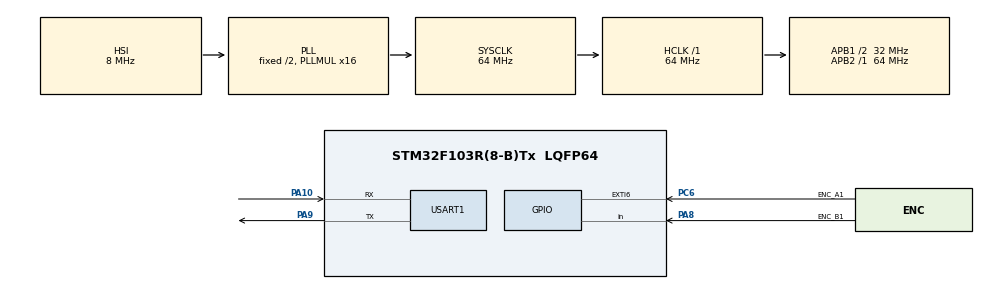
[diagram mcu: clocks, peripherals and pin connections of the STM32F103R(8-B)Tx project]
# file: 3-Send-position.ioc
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Dma.Request0=USART1_TX
Dma.USART1_TX.0.Direction=DMA_MEMORY_TO_PERIPH
Dma.USART1_TX.0.Instance=DMA1_Channel4
Dma.USART1_TX.0.MemDataAlignment=DMA_MDATAALIGN_BYTE
Dma.USART1_TX.0.MemInc=DMA_MINC_ENABLE
Dma.USART1_TX.0.Mode=DMA_NORMAL
Dma.USART1_TX.0.PeriphDataAlignment=DMA_PDATAALIGN_BYTE
Dma.USART1_TX.0.PeriphInc=DMA_PINC_DISABLE
Dma.USART1_TX.0.Priority=DMA_PRIORITY_HIGH
Mcu.Family=STM32F1
Mcu.Name=STM32F103R(8-B)Tx
Mcu.Package=LQFP64
NVIC.DMA1_Channel4_IRQn=true\:0\:0\:false\:false\:true\:false\:true\:true
NVIC.EXTI9_5_IRQn=true\:0\:0\:false\:false\:true\:true\:true\:true
NVIC.PriorityGroup=NVIC_PRIORITYGROUP_4
NVIC.USART1_IRQn=true\:0\:0\:false\:false\:true\:true\:true\:true
PA10.Mode=Asynchronous
PA10.Signal=USART1_RX
PA13.Mode=Serial_Wire
PA13.Signal=SYS_JTMS-SWDIO
PA14.Mode=Serial_Wire
PA14.Signal=SYS_JTCK-SWCLK
PA8.GPIO_Label=ENC_B1
PA8.Signal=GPIO_Input
PA9.Mode=Asynchronous
PA9.Signal=USART1_TX
PC6.GPIO_Label=ENC_A1
PC6.Signal=GPXTI6
ProjectManager.HeapSize=0x200
ProjectManager.StackSize=0x400
ProjectManager.TargetToolchain=MDK-ARM V5.32
RCC.AHBFreq_Value=64000000
RCC.APB1CLKDivider=RCC_HCLK_DIV2
RCC.APB1Freq_Value=32000000
RCC.APB1TimFreq_Value=64000000
RCC.APB2Freq_Value=64000000
RCC.APB2TimFreq_Value=64000000
RCC.HCLKFreq_Value=64000000
RCC.PLLMUL=RCC_PLL_MUL16
RCC.SYSCLKFreq_VALUE=64000000
RCC.SYSCLKSource=RCC_SYSCLKSOURCE_PLLCLK
RCC.USBFreq_Value=64000000
USART1.VirtualMode=VM_ASYNC
board=custom

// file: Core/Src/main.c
/* USER CODE BEGIN Header */
/**
  ******************************************************************************
  * @file           : main.c
  * @brief          : Main program body
  ******************************************************************************
  * @attention
  *
  * Copyright (c) 2026 STMicroelectronics.
  * All rights reserved.
  *
  * This software is licensed under terms that can be found in the LICENSE file
  * in the root directory of this software component.
  * If no LICENSE file comes with this software, it is provided AS-IS.
  *
  ******************************************************************************
  */
/* USER CODE END Header */
#include "main.h"

/* USER CODE BEGIN Includes */
#include "MyApp.h"
#include "ReadENC.h"
#include "command_parser.h"

/* USER CODE END Includes */

UART_HandleTypeDef huart1;
DMA_HandleTypeDef hdma_usart1_tx;

void SystemClock_Config(void);
static void MX_GPIO_Init(void);
static void MX_DMA_Init(void);
static void MX_USART1_UART_Init(void);

int main(void)
{

  /* MCU Configuration--------------------------------------------------------*/

  /* Reset of all peripherals, Initializes the Flash interface and the Systick. */
  HAL_Init();

  /* USER CODE BEGIN Init */
	Encoder_Init();

  /* USER CODE END Init */

  /* Configure the system clock */
  SystemClock_Config();

  /* Initialize all configured peripherals */
  MX_GPIO_Init();
  MX_DMA_Init();
  MX_USART1_UART_Init();
  /* USER CODE BEGIN 2 */
	UART_RX_IT_Init();
  /* USER CODE END 2 */

  /* Infinite loop */
  while (1)
  {

    /* USER CODE BEGIN 3 */

		UART_TX_Task();
		My_App();
  }
  /* USER CODE END 3 */
}

void SystemClock_Config(void)
{
  RCC_OscInitTypeDef RCC_OscInitStruct = {0};
  RCC_ClkInitTypeDef RCC_ClkInitStruct = {0};

  /** Initializes the RCC Oscillators according to the specified parameters
  * in the RCC_OscInitTypeDef structure.
  */
  RCC_OscInitStruct.OscillatorType = RCC_OSCILLATORTYPE_HSI;
  RCC_OscInitStruct.HSIState = RCC_HSI_ON;
  RCC_OscInitStruct.HSICalibrationValue = RCC_HSICALIBRATION_DEFAULT;
  RCC_OscInitStruct.PLL.PLLState = RCC_PLL_ON;
  RCC_OscInitStruct.PLL.PLLSource = RCC_PLLSOURCE_HSI_DIV2;
  RCC_OscInitStruct.PLL.PLLMUL = RCC_PLL_MUL16;
  if (HAL_RCC_OscConfig(&RCC_OscInitStruct) != HAL_OK)
  {
    Error_Handler();
  }

  /** Initializes the CPU, AHB and APB buses clocks
  */
  RCC_ClkInitStruct.ClockType = RCC_CLOCKTYPE_HCLK|RCC_CLOCKTYPE_SYSCLK
                              |RCC_CLOCKTYPE_PCLK1|RCC_CLOCKTYPE_PCLK2;
  RCC_ClkInitStruct.SYSCLKSource = RCC_SYSCLKSOURCE_PLLCLK;
  RCC_ClkInitStruct.AHBCLKDivider = RCC_SYSCLK_DIV1;
  RCC_ClkInitStruct.APB1CLKDivider = RCC_HCLK_DIV2;
  RCC_ClkInitStruct.APB2CLKDivider = RCC_HCLK_DIV1;

  if (HAL_RCC_ClockConfig(&RCC_ClkInitStruct, FLASH_LATENCY_2) != HAL_OK)
  {
    Error_Handler();
  }
}

static void MX_USART1_UART_Init(void)
{

  huart1.Instance = USART1;
  huart1.Init.BaudRate = 115200;
  huart1.Init.WordLength = UART_WORDLENGTH_8B;
  huart1.Init.StopBits = UART_STOPBITS_1;
  huart1.Init.Parity = UART_PARITY_NONE;
  huart1.Init.Mode = UART_MODE_TX_RX;
  huart1.Init.HwFlowCtl = UART_HWCONTROL_NONE;
  huart1.Init.OverSampling = UART_OVERSAMPLING_16;
  if (HAL_UART_Init(&huart1) != HAL_OK)
  {
    Error_Handler();
  }
  /* USER CODE BEGIN USART1_Init 2 */
 __HAL_LINKDMA(&huart1, hdmatx, hdma_usart1_tx);
  /* USER CODE END USART1_Init 2 */

}

static void MX_DMA_Init(void)
{

  /* DMA controller clock enable */
  __HAL_RCC_DMA1_CLK_ENABLE();

  /* DMA interrupt init */
  /* DMA1_Channel4_IRQn interrupt configuration */
  HAL_NVIC_SetPriority(DMA1_Channel4_IRQn, 0, 0);
  HAL_NVIC_EnableIRQ(DMA1_Channel4_IRQn);

}

static void MX_GPIO_Init(void)
{
  GPIO_InitTypeDef GPIO_InitStruct = {0};

  /* GPIO Ports Clock Enable */
  __HAL_RCC_GPIOC_CLK_ENABLE();
  __HAL_RCC_GPIOD_CLK_ENABLE();
  __HAL_RCC_GPIOA_CLK_ENABLE();
  __HAL_RCC_GPIOB_CLK_ENABLE();

  /*Configure GPIO pins : PC13 PC14 PC15 PC0
                           PC1 PC2 PC3 PC4
                           PC5 PC7 PC8 PC9
                           PC10 PC11 PC12 */
  GPIO_InitStruct.Pin = GPIO_PIN_13|GPIO_PIN_14|GPIO_PIN_15|GPIO_PIN_0
                          |GPIO_PIN_1|GPIO_PIN_2|GPIO_PIN_3|GPIO_PIN_4
                          |GPIO_PIN_5|GPIO_PIN_7|GPIO_PIN_8|GPIO_PIN_9
                          |GPIO_PIN_10|GPIO_PIN_11|GPIO_PIN_12;
  GPIO_InitStruct.Mode = GPIO_MODE_ANALOG;
  HAL_GPIO_Init(GPIOC, &GPIO_InitStruct);

  /*Configure GPIO pins : PD0 PD1 PD2 */
  GPIO_InitStruct.Pin = GPIO_PIN_0|GPIO_PIN_1|GPIO_PIN_2;
  GPIO_InitStruct.Mode = GPIO_MODE_ANALOG;
  HAL_GPIO_Init(GPIOD, &GPIO_InitStruct);

  /*Configure GPIO pins : PA0 PA1 PA2 PA3
                           PA4 PA5 PA6 PA7
                           PA11 PA12 PA15 */
  GPIO_InitStruct.Pin = GPIO_PIN_0|GPIO_PIN_1|GPIO_PIN_2|GPIO_PIN_3
                          |GPIO_PIN_4|GPIO_PIN_5|GPIO_PIN_6|GPIO_PIN_7
                          |GPIO_PIN_11|GPIO_PIN_12|GPIO_PIN_15;
  GPIO_InitStruct.Mode = GPIO_MODE_ANALOG;
  HAL_GPIO_Init(GPIOA, &GPIO_InitStruct);

  /*Configure GPIO pins : PB0 PB1 PB2 PB10
                           PB11 PB12 PB13 PB14
                           PB15 PB3 PB4 PB5
                           PB6 PB7 PB8 PB9 */
  GPIO_InitStruct.Pin = GPIO_PIN_0|GPIO_PIN_1|GPIO_PIN_2|GPIO_PIN_10
                          |GPIO_PIN_11|GPIO_PIN_12|GPIO_PIN_13|GPIO_PIN_14
                          |GPIO_PIN_15|GPIO_PIN_3|GPIO_PIN_4|GPIO_PIN_5
                          |GPIO_PIN_6|GPIO_PIN_7|GPIO_PIN_8|GPIO_PIN_9;
  GPIO_InitStruct.Mode = GPIO_MODE_ANALOG;
  HAL_GPIO_Init(GPIOB, &GPIO_InitStruct);

  /*Configure GPIO pin : ENC_A1_Pin */
  GPIO_InitStruct.Pin = ENC_A1_Pin;
  GPIO_InitStruct.Mode = GPIO_MODE_IT_RISING;
  GPIO_InitStruct.Pull = GPIO_NOPULL;
  HAL_GPIO_Init(ENC_A1_GPIO_Port, &GPIO_InitStruct);

  /*Configure GPIO pin : ENC_B1_Pin */
  GPIO_InitStruct.Pin = ENC_B1_Pin;
  GPIO_InitStruct.Mode = GPIO_MODE_INPUT;
  GPIO_InitStruct.Pull = GPIO_NOPULL;
  HAL_GPIO_Init(ENC_B1_GPIO_Port, &GPIO_InitStruct);

  /*Configure peripheral I/O remapping */
  __HAL_AFIO_REMAP_PD01_ENABLE();

  /* EXTI interrupt init*/
  HAL_NVIC_SetPriority(EXTI9_5_IRQn, 0, 0);
  HAL_NVIC_EnableIRQ(EXTI9_5_IRQn);

}

void Error_Handler(void)
{
  __disable_irq();
  while (1)
  {
  }
}
